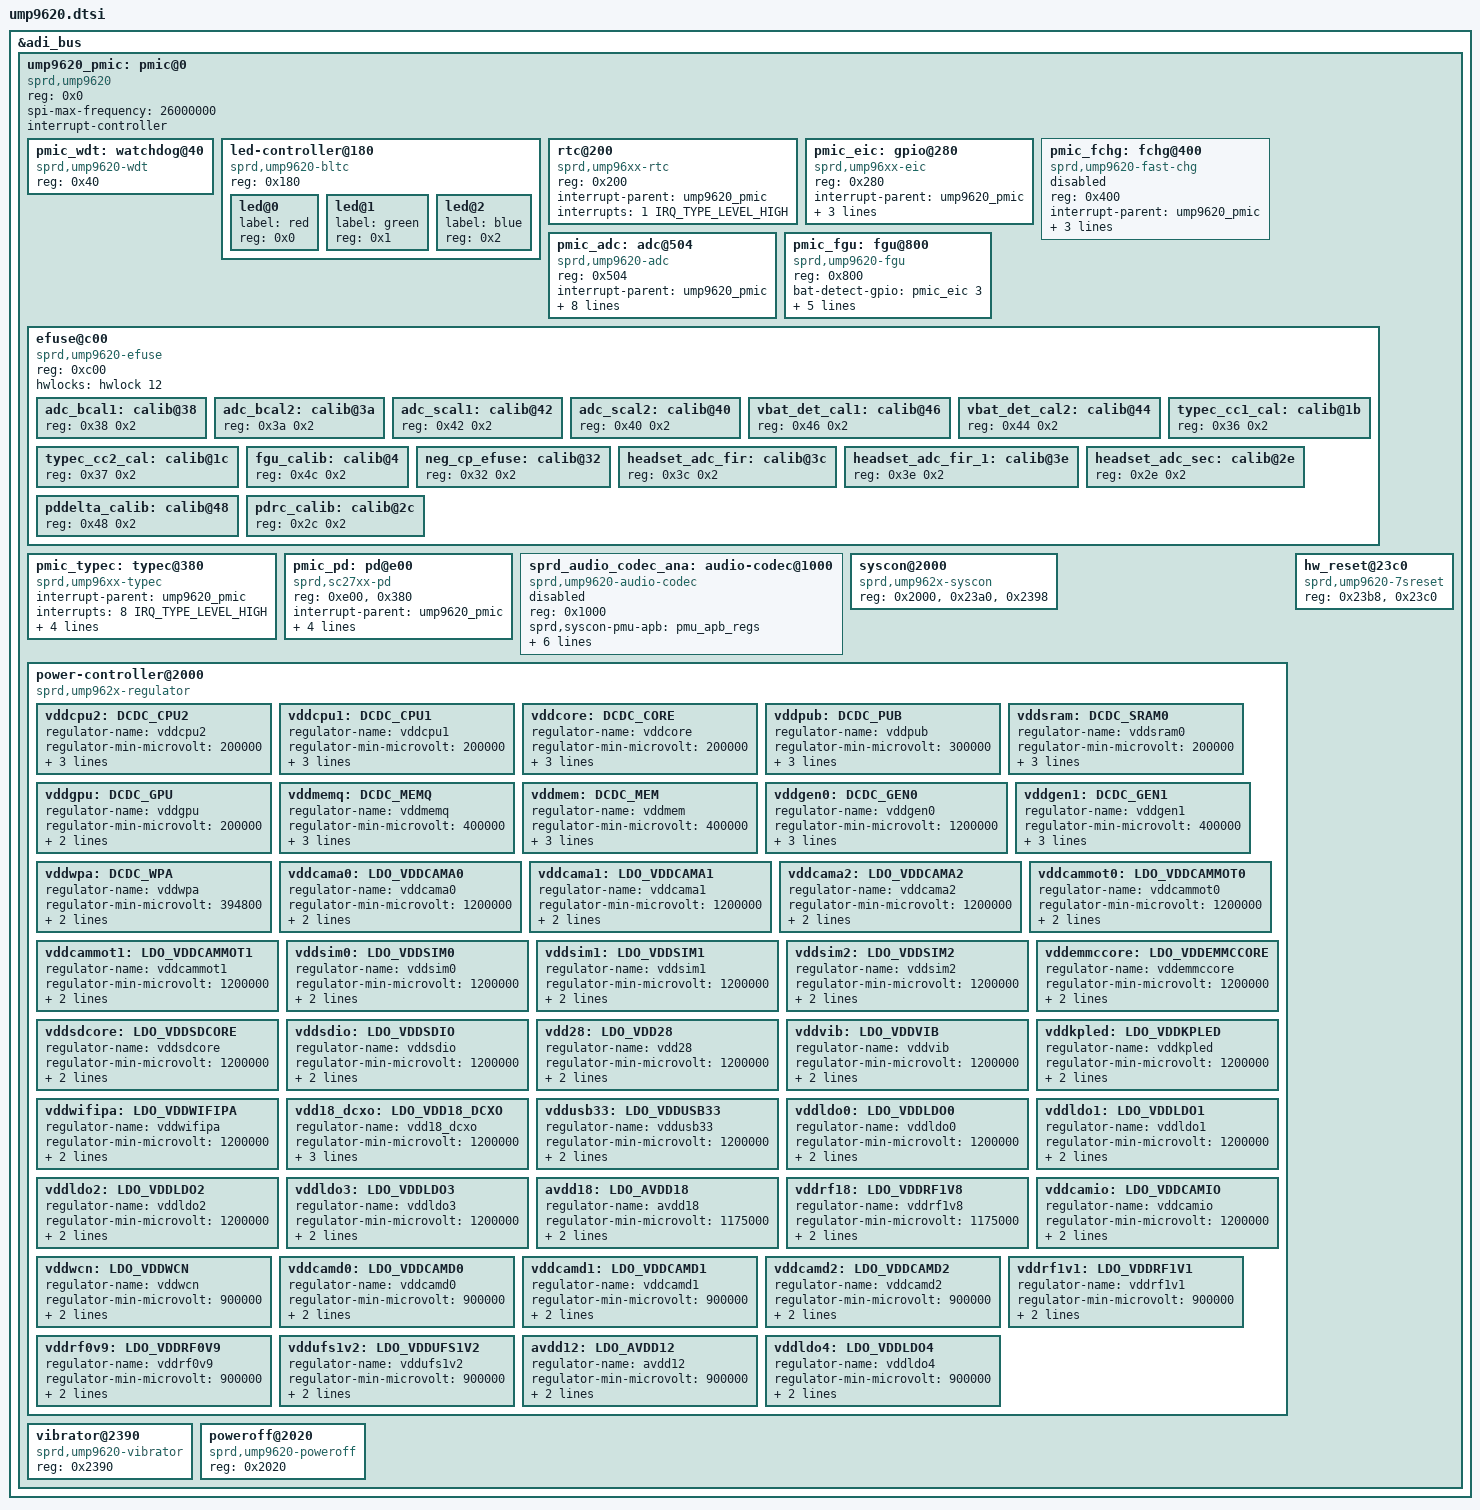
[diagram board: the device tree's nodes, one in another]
/*
 * UNISOC UMP9620 PMIC dts file
 *
 * Copyright (C) 2020, UNISOC Communications Inc.
 *
 * SPDX-License-Identifier: (GPL-2.0+ OR MIT)
 */

&adi_bus {
	ump9620_pmic: pmic@0 {
		compatible = "sprd,ump9620";
		reg = <0x0>;
		spi-max-frequency = <26000000>;
		interrupt-controller;
		#interrupt-cells = <2>;
		#address-cells = <1>;
		#size-cells = <0>;

		pmic_wdt: watchdog@40 {
			compatible = "sprd,ump9620-wdt", "sprd,sc27xx-wdt";
			reg = <0x40>;
		};

		led-controller@180 {
			compatible = "sprd,ump9620-bltc", "sprd,sc27xx-bltc";
			#address-cells = <1>;
			#size-cells = <0>;
			reg = <0x180>;

			led@0 {
				label = "red";
				reg = <0x0>;
			};

			led@1 {
				label = "green";
				reg = <0x1>;
			};

			led@2 {
				label = "blue";
				reg = <0x2>;
			};
		};

		rtc@200 {
			compatible = "sprd,ump96xx-rtc", "sprd,sc27xx-rtc";
			reg = <0x200>;
			interrupt-parent = <&ump9620_pmic>;
			interrupts = <1 IRQ_TYPE_LEVEL_HIGH>;
		};

		pmic_eic: gpio@280 {
			compatible = "sprd,ump96xx-eic", "sprd,sc27xx-eic";
			reg = <0x280>;
			interrupt-parent = <&ump9620_pmic>;
			interrupts = <4 IRQ_TYPE_LEVEL_HIGH>;
			gpio-controller;
			#gpio-cells = <2>;
			interrupt-controller;
			#interrupt-cells = <2>;
		};

		pmic_fchg: fchg@400 {
			compatible = "sprd,ump9620-fast-chg", "sprd,sc27xx-fast-chg";
			reg = <0x400>;
			interrupt-parent = <&ump9620_pmic>;
			interrupts = <5 IRQ_TYPE_LEVEL_HIGH>;
			nvmem-cell-names = "fchg_cur_calib";
			nvmem-cells = <&headset_adc_fir>;
			status = "disabled";
		};

		pmic_adc: adc@504 {
			compatible = "sprd,ump9620-adc", "sprd,sc27xx-adc";
			reg = <0x504>;
			interrupt-parent = <&ump9620_pmic>;
			interrupts = <0 IRQ_TYPE_LEVEL_HIGH>;
			#io-channel-cells = <1>;
			hwlocks = <&hwlock 4>;
			nvmem-cells = <&adc_bcal1>, <&adc_bcal2>, <&adc_scal1>, <&adc_scal2>, <&vbat_det_cal1>, <&vbat_det_cal2>;
			nvmem-cell-names = "big_scale_calib1", "big_scale_calib2", "small_scale_calib1", "small_scale_calib2", "vbat_det_cal1", "vbat_det_cal2";
		};

		pmic_fgu: fgu@800 {
			compatible = "sprd,ump9620-fgu", "sprd,sc27xx-fgu";
			reg = <0x800>;
			bat-detect-gpio = <&pmic_eic 3 GPIO_ACTIVE_HIGH>;
			nvmem-cell-names = "fgu_calib";
			nvmem-cells = <&fgu_calib>;
			io-channels = <&pmic_adc 0>, <&pmic_adc 14>;
			io-channel-names = "bat-temp", "charge-vol";
			interrupt-parent = <&ump9620_pmic>;
			interrupts = <3 IRQ_TYPE_LEVEL_HIGH>;
		};

		efuse@c00 {
			compatible = "sprd,ump9620-efuse", "sprd,sc27xx-efuse";
			reg = <0xc00>;
			#address-cells = <1>;
			#size-cells = <1>;
			hwlocks = <&hwlock 12>;
			/* Data cells */
			adc_bcal1: calib@38 {
				reg = <0x38 0x2>;
			};

			adc_bcal2: calib@3a {
				reg = <0x3a 0x2>;
			};

			adc_scal1: calib@42 {
				reg = <0x42 0x2>;
			};

			adc_scal2: calib@40 {
				reg = <0x40 0x2>;
			};

			vbat_det_cal1: calib@46 {
				reg = <0x46 0x2>;
			};

			vbat_det_cal2: calib@44 {
				reg = <0x44 0x2>;
			};

			typec_cc1_cal: calib@1b {
				reg = <0x36 0x2>;
			};

			typec_cc2_cal: calib@1c {
				reg = <0x37 0x2>;
			};

			fgu_calib: calib@4 {
				reg = <0x4c 0x2>;
			};

			neg_cp_efuse: calib@32 {
				reg = <0x32 0x2>;
			};

			headset_adc_fir: calib@3c {
				reg = <0x3c 0x2>;
			};

			headset_adc_fir_1: calib@3e {
				reg = <0x3e 0x2>;
			};

			headset_adc_sec: calib@2e {
				reg = <0x2e 0x2>;
			};

			pddelta_calib: calib@48 {
				reg = <0x48 0x2>;
			};

			pdrc_calib: calib@2c {
				reg = <0x2c 0x2>;
			};
		};

		pmic_typec: typec@380 {
			compatible = "sprd,ump96xx-typec", "sprd,sc27xx-typec";
			interrupt-parent = <&ump9620_pmic>;
			interrupts = <8 IRQ_TYPE_LEVEL_HIGH>;
			reg = <0x380>;
			mode = <2>;
			nvmem-cells = <&typec_cc1_cal>, <&typec_cc2_cal>;
			nvmem-cell-names = "typec_cc1_cal", "typec_cc2_cal";
		};

		pmic_pd: pd@e00 {
			compatible = "sprd,sc27xx-pd", "sprd,ump9620-pd";
			reg = <0xe00>, <0x380>;
			interrupt-parent = <&ump9620_pmic>;
			interrupts = <9 IRQ_TYPE_LEVEL_HIGH>;
			extcon = <&pmic_typec>;
			nvmem-cells = <&pdrc_calib>, <&pddelta_calib>;
			nvmem-cell-names = "pdrc_calib", "pddelta_calib";
		};

		sprd_audio_codec_ana: audio-codec@1000 {
			compatible = "sprd,ump9620-audio-codec",
				"sprd,sc27xx-audio-codec";
			#sound-dai-cells = <1>;
			reg = <0x1000>;
			sprd,syscon-pmu-apb = <&pmu_apb_regs>;
			sprd,syscon-aon-apb = <&aon_apb_regs>;
			syscons = <&aon_apb_regs REG_AON_APB_MIPI_CSI_POWER_CTRL
				MASK_AON_APB_R2G_ANALOG_BB_TOP_SINDRV_ENA_CAL>;
			syscon-names = "clk26m_sinout_pmic_en";
			nvmem-cells = <&neg_cp_efuse>,
				<&fgu_calib>;
			nvmem-cell-names = "neg_cp_efuse",
					"fgu_4p2_efuse";
			status = "disabled";
		};

		syscon@2000 {
			compatible = "sprd,ump962x-syscon";
			reg = <0x2000>, <0x23a0>, <0x2398>;
		};

		power-controller@2000 {
			compatible = "sprd,ump962x-regulator", "sprd,sc27xx-regulator";

			vddcpu2: DCDC_CPU2 {
				regulator-name = "vddcpu2";
				regulator-min-microvolt = <200000>;
				regulator-max-microvolt = <1596875>;
				regulator-ramp-delay = <25000>;
				regulator-always-on;
			};

			vddcpu1: DCDC_CPU1 {
				regulator-name = "vddcpu1";
				regulator-min-microvolt = <200000>;
				regulator-max-microvolt = <1596875>;
				regulator-ramp-delay = <25000>;
				regulator-always-on;
			};

			vddcore: DCDC_CORE {
				regulator-name = "vddcore";
				regulator-min-microvolt = <200000>;
				regulator-max-microvolt = <1596875>;
				regulator-ramp-delay = <25000>;
				regulator-always-on;
			};

			vddpub: DCDC_PUB {
				regulator-name = "vddpub";
				regulator-min-microvolt = <300000>;
				regulator-max-microvolt = <1596875>;
				regulator-ramp-delay = <25000>;
				regulator-always-on;
			};

			vddsram: DCDC_SRAM0 {
				regulator-name = "vddsram0";
				regulator-min-microvolt = <200000>;
				regulator-max-microvolt = <1596875>;
				regulator-ramp-delay = <25000>;
				regulator-always-on;
			};

			vddgpu: DCDC_GPU {
				regulator-name = "vddgpu";
				regulator-min-microvolt = <200000>;
				regulator-max-microvolt = <1596875>;
				regulator-ramp-delay = <25000>;
			};

			vddmemq: DCDC_MEMQ {
				regulator-name = "vddmemq";
				regulator-min-microvolt = <400000>;
				regulator-max-microvolt = <1596875>;
				regulator-ramp-delay = <25000>;
				regulator-always-on;
			};

			vddmem: DCDC_MEM {
				regulator-name = "vddmem";
				regulator-min-microvolt = <400000>;
				regulator-max-microvolt = <1593750>;
				regulator-ramp-delay = <25000>;
				regulator-always-on;
			};

			vddgen0: DCDC_GEN0 {
				regulator-name = "vddgen0";
				regulator-min-microvolt = <1200000>;
				regulator-max-microvolt = <2390625>;
				regulator-ramp-delay = <25000>;
				regulator-always-on;
			};

			vddgen1: DCDC_GEN1 {
				regulator-name = "vddgen1";
				regulator-min-microvolt = <400000>;
				regulator-max-microvolt = <1593750>;
				regulator-ramp-delay = <25000>;
				regulator-always-on;
			};

			vddwpa: DCDC_WPA {
				regulator-name = "vddwpa";
				regulator-min-microvolt = <394800>;
				regulator-max-microvolt = <3595500>;
				regulator-ramp-delay = <25000>;
			};

			vddcama0: LDO_VDDCAMA0 {
				regulator-name = "vddcama0";
				regulator-min-microvolt = <1200000>;
				regulator-max-microvolt = <3750000>;
				regulator-ramp-delay = <25000>;
			};

			vddcama1: LDO_VDDCAMA1 {
				regulator-name = "vddcama1";
				regulator-min-microvolt = <1200000>;
				regulator-max-microvolt = <3750000>;
				regulator-ramp-delay = <25000>;
			};

			vddcama2: LDO_VDDCAMA2 {
				regulator-name = "vddcama2";
				regulator-min-microvolt = <1200000>;
				regulator-max-microvolt = <3750000>;
				regulator-ramp-delay = <25000>;
			};

			vddcammot0: LDO_VDDCAMMOT0 {
				regulator-name = "vddcammot0";
				regulator-min-microvolt = <1200000>;
				regulator-max-microvolt = <3750000>;
				regulator-ramp-delay = <25000>;
			};

			vddcammot1: LDO_VDDCAMMOT1 {
				regulator-name = "vddcammot1";
				regulator-min-microvolt = <1200000>;
				regulator-max-microvolt = <3750000>;
				regulator-ramp-delay = <25000>;
			};

			vddsim0: LDO_VDDSIM0 {
				regulator-name = "vddsim0";
				regulator-min-microvolt = <1200000>;
				regulator-max-microvolt = <3750000>;
				regulator-ramp-delay = <25000>;
			};

			vddsim1: LDO_VDDSIM1 {
				regulator-name = "vddsim1";
				regulator-min-microvolt = <1200000>;
				regulator-max-microvolt = <3750000>;
				regulator-ramp-delay = <25000>;
			};

			vddsim2: LDO_VDDSIM2 {
				regulator-name = "vddsim2";
				regulator-min-microvolt = <1200000>;
				regulator-max-microvolt = <3750000>;
				regulator-ramp-delay = <25000>;
			};

			vddemmccore: LDO_VDDEMMCCORE {
				regulator-name = "vddemmccore";
				regulator-min-microvolt = <1200000>;
				regulator-max-microvolt = <3750000>;
				regulator-ramp-delay = <25000>;
			};

			vddsdcore: LDO_VDDSDCORE {
				regulator-name = "vddsdcore";
				regulator-min-microvolt = <1200000>;
				regulator-max-microvolt = <3750000>;
				regulator-ramp-delay = <25000>;
			};

			vddsdio: LDO_VDDSDIO {
				regulator-name = "vddsdio";
				regulator-min-microvolt = <1200000>;
				regulator-max-microvolt = <3750000>;
				regulator-ramp-delay = <25000>;
			};

			vdd28: LDO_VDD28 {
				regulator-name = "vdd28";
				regulator-min-microvolt = <1200000>;
				regulator-max-microvolt = <3750000>;
				regulator-ramp-delay = <25000>;
			};

			vddvib: LDO_VDDVIB {
				regulator-name = "vddvib";
				regulator-min-microvolt = <1200000>;
				regulator-max-microvolt = <3750000>;
				regulator-ramp-delay = <25000>;
			};

			vddkpled: LDO_VDDKPLED {
				regulator-name = "vddkpled";
				regulator-min-microvolt = <1200000>;
				regulator-max-microvolt = <3750000>;
				regulator-ramp-delay = <25000>;
			};

			vddwifipa: LDO_VDDWIFIPA {
				regulator-name = "vddwifipa";
				regulator-min-microvolt = <1200000>;
				regulator-max-microvolt = <3750000>;
				regulator-ramp-delay = <25000>;
			};

			vdd18_dcxo: LDO_VDD18_DCXO {
				regulator-name = "vdd18_dcxo";
				regulator-min-microvolt = <1200000>;
				regulator-max-microvolt = <3750000>;
				regulator-ramp-delay = <25000>;
				regulator-always-on;
			};

			vddusb33: LDO_VDDUSB33 {
				regulator-name = "vddusb33";
				regulator-min-microvolt = <1200000>;
				regulator-max-microvolt = <3750000>;
				regulator-ramp-delay = <25000>;
			};

			vddldo0: LDO_VDDLDO0 {
				regulator-name = "vddldo0";
				regulator-min-microvolt = <1200000>;
				regulator-max-microvolt = <3750000>;
				regulator-ramp-delay = <25000>;
			};

			vddldo1: LDO_VDDLDO1 {
				regulator-name = "vddldo1";
				regulator-min-microvolt = <1200000>;
				regulator-max-microvolt = <3750000>;
				regulator-ramp-delay = <25000>;
			};

			vddldo2: LDO_VDDLDO2 {
				regulator-name = "vddldo2";
				regulator-min-microvolt = <1200000>;
				regulator-max-microvolt = <3750000>;
				regulator-ramp-delay = <25000>;
			};

			vddldo3: LDO_VDDLDO3 {
				regulator-name = "vddldo3";
				regulator-min-microvolt = <1200000>;
				regulator-max-microvolt = <3750000>;
				regulator-ramp-delay = <25000>;
			};

			avdd18: LDO_AVDD18 {
				regulator-name = "avdd18";
				regulator-min-microvolt = <1175000>;
				regulator-max-microvolt = <1805000>;
				regulator-ramp-delay = <25000>;
			};

			vddrf18: LDO_VDDRF1V8 {
				regulator-name = "vddrf1v8";
				regulator-min-microvolt = <1175000>;
				regulator-max-microvolt = <1805000>;
				regulator-ramp-delay = <25000>;
			};

			vddcamio: LDO_VDDCAMIO {
				regulator-name = "vddcamio";
				regulator-min-microvolt = <1200000>;
				regulator-max-microvolt = <1830000>;
				regulator-ramp-delay = <25000>;
			};

			vddwcn: LDO_VDDWCN {
				regulator-name = "vddwcn";
				regulator-min-microvolt = <900000>;
				regulator-max-microvolt = <1845000>;
				regulator-ramp-delay = <25000>;
			};

			vddcamd0: LDO_VDDCAMD0 {
				regulator-name = "vddcamd0";
				regulator-min-microvolt = <900000>;
				regulator-max-microvolt = <1365000>;
				regulator-ramp-delay = <25000>;
			};

			vddcamd1: LDO_VDDCAMD1 {
				regulator-name = "vddcamd1";
				regulator-min-microvolt = <900000>;
				regulator-max-microvolt = <1365000>;
				regulator-ramp-delay = <25000>;
			};

			vddcamd2: LDO_VDDCAMD2 {
				regulator-name = "vddcamd2";
				regulator-min-microvolt = <900000>;
				regulator-max-microvolt = <1365000>;
				regulator-ramp-delay = <25000>;
			};

			vddrf1v1: LDO_VDDRF1V1 {
				regulator-name = "vddrf1v1";
				regulator-min-microvolt = <900000>;
				regulator-max-microvolt = <1365000>;
				regulator-ramp-delay = <25000>;
			};

			vddrf0v9: LDO_VDDRF0V9 {
				regulator-name = "vddrf0v9";
				regulator-min-microvolt = <900000>;
				regulator-max-microvolt = <1365000>;
				regulator-ramp-delay = <25000>;
			};

			vddufs1v2: LDO_VDDUFS1V2 {
				regulator-name = "vddufs1v2";
				regulator-min-microvolt = <900000>;
				regulator-max-microvolt = <1365000>;
				regulator-ramp-delay = <25000>;
			};

			avdd12: LDO_AVDD12 {
				regulator-name = "avdd12";
				regulator-min-microvolt = <900000>;
				regulator-max-microvolt = <1365000>;
				regulator-ramp-delay = <25000>;
			};

			vddldo4: LDO_VDDLDO4 {
				regulator-name = "vddldo4";
				regulator-min-microvolt = <900000>;
				regulator-max-microvolt = <1365000>;
				regulator-ramp-delay = <25000>;
			};
		};

		vibrator@2390 {
			compatible = "sprd,ump9620-vibrator", "sprd,sc27xx-vibrator";
			reg = <0x2390>;
		};

		hw_reset@23c0 {
			compatible = "sprd,ump9620-7sreset", "sprd,sc27xx-7sreset";
			reg = <0x23b8>, <0x23c0>;
		};

		poweroff@2020 {
			compatible = "sprd,ump9620-poweroff", "sprd,sc27xx-poweroff";
			reg = <0x2020>;
		};
	};
};
